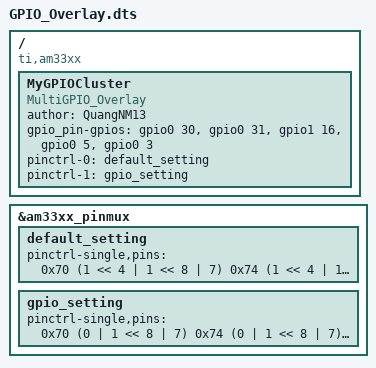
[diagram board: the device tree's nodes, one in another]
/dts-v1/;
/plugin/;
/*
LED1  ---------------------- GPIO0_30       GPIO_30
LED2  ---------------------- GPIO0_31       GPIO_31
LED3  ---------------------- GPIO1_16       GPIO_48
LED4  ---------------------- GPIO0_05       GPIO_05
LED5  ---------------------- GPIO0_03       GPIO_03
*/

/{
    compatible = "ti,am33xx";
    fragment@0 {
            target = <&am33xx_pinmux>;
            __overlay__ {
                default_setting: default_setting {
                    pinctrl-single,pins = <
                        0x70  (1 << 4 | 1 << 8 | 7)
                        0x74  (1 << 4 | 1 << 8 | 7)
                        0x40  (1 << 3 | 1 << 8 | 7)
                        0x15c (1 << 4 | 1 << 8 | 7)
                        0x154 (1 << 4 | 1 << 8 | 7)
                    >;
                };

                gpio_setting: gpio_setting {
                    pinctrl-single,pins = <
                        0x70  (0 | 1 << 8 | 7)
                        0x74  (0 | 1 << 8 | 7)
                        0x40  (0 | 1 << 8 | 7)
                        0x15c (0 | 1 << 8 | 7)
                        0x154 (0 | 1 << 8 | 7)
                    >;
                };
            };
    };

    fragment@1 {
        target-path = "/";
        __overlay__ {
            MyGPIOCluster {
                compatible = "MultiGPIO_Overlay";
                author = "QuangNM13";
                status = "okay";
                gpio_pin-gpios = <&gpio0 30 0>,
                                <&gpio0 31 0>,
                                <&gpio1 16 0>,
                                <&gpio0 5 0>,
                                <&gpio0 3 0>;
                pinctrl-names = "default", "gpio";
		        pinctrl-0 = <&default_setting>;
		        pinctrl-1 = <&gpio_setting>;
            };
        }; 
    };
};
